# CH32F103xx register map
Vendor: WCH Ltd.; File version: 1.0
Registers are 32-bit, read-write, reset 0x0 unless marked. A register's access mark holds for its fields unless they carry their own. Offsets are from the block's base; [hi:lo] are bit positions; {n}, {i} and the like mark numbered series.

## DBG — Debug support
Base 0xE000D000
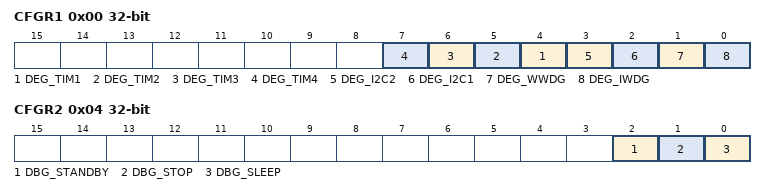
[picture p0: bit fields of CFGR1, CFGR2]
0x00 CFGR1 — DBGMCU_CFGR1
  [n+3] DEG_TIM{n} (n=1..4), [3] DEG_I2C2, [2] DEG_I2C1, [1] DEG_WWDG, [0] DEG_IWDG
0x04 CFGR2 — DBGMCU_CFGR2
  [2] DBG_STANDBY, [1] DBG_STOP, [0] DBG_SLEEP

## CRC — CRC calculation unit
Base 0x40023000
0x00 DATAR reset 0xFFFFFFFF — Data register
  [31:0] DR — Data Register
0x04 IDATAR — Independent Data register
  [7:0] IDR
0x08 CTLR wo — Control register
  [0] RESET — Reset bit

## FLASH
Base 0x40022000
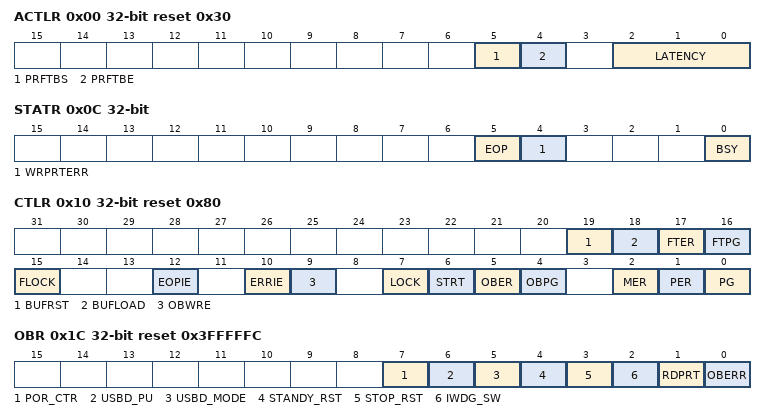
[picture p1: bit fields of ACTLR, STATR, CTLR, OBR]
0x00 ACTLR access per field reset 0x30 — Flash access control register
  [5] PRFTBS ro — Prefetch buffer status
  [4] PRFTBE rw — Prefetch buffer enable
  [2:0] LATENCY rw
0x04 KEYR wo — Flash key register
  [31:0] KEYR — FPEC key
0x08 OBKEYR wo — Flash option key register
  [31:0] OPTKEY — Option byte key
0x0C STATR access per field — Status register
  [5] EOP rw — End of operation
  [4] WRPRTERR rw — Write protection error
  [0] BSY ro — Busy
0x10 CTLR reset 0x80 — Control register
  [19] BUFRST — Buffer reset
  [18] BUFLOAD — Buffer load
  [17] FTER — Fast erase
  [16] FTPG — Fast programming
  [15] FLOCK — Fast programmable lock
  [12] EOPIE — End of operation interrupt enable
  [10] ERRIE — Error interrupt enable
  [9] OBWRE — Option bytes write enable
  [7] LOCK
  [6] STRT — Start
  [5] OBER — Option byte erase
  [4] OBPG — Option byte programming
  [2] MER — Mass Erase
  [1] PER — Page Erase
  [0] PG — Programming
0x14 ADDR wo — Flash address register
  [31:0] FAR — Flash Address
0x1C OBR ro reset 0x3FFFFFC — Option byte register
  [7] POR_CTR
  [6] USBD_PU
  [5] USBD_MODE
  [4] STANDY_RST
  [3] STOP_RST
  [2] IWDG_SW
  [1] RDPRT — Read protection
  [0] OBERR — Option byte error
0x20 WPR ro reset 0xFFFFFFFF — Write protection register
  [31:0] WRP — Write protect
0x24 MODEKEYR wo — Mode select register
  [31:0] MODEKEYR — Mode select

## PFIC — Programmable Fast Interrupt Controller
Base 0xE000E000
0x00 ISR1 ro — Interrupt Status Register
  [31:0] INTS — Interrupt ID Status
0x04 ISR2 ro — Interrupt Status Register
  [31:0] INTS — Interrupt ID Status
0x20 IPR1 ro — Interrupt Pending Register
  [31:0] PENDSTA
0x24 IPR2 ro — Interrupt Pending Register
  [31:0] PENDSTA
0x40 ITHRESDR — Interrupt Priority Register
  [7:0] THRESHOLD
0x44 FIBADDRR — Interrupt Fast Address Register
  [31:28] BASEADDR
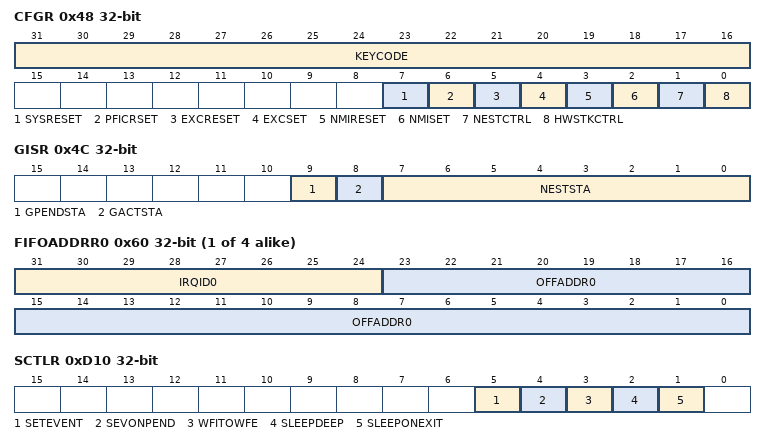
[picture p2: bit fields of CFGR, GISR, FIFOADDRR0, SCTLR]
0x48 CFGR access per field — Interrupt Config Register
  [31:16] KEYCODE wo, [7] SYSRESET wo, [6] PFICRSET wo, [5] EXCRESET wo, [4] EXCSET wo, [3] NMIRESET wo, [2] NMISET wo, [1] NESTCTRL rw, [0] HWSTKCTRL rw
0x4C GISR ro — Interrupt Global Register
  [9] GPENDSTA, [8] GACTSTA, [7:0] NESTSTA
{0x60+4i} FIFOADDRR{i} (i=0..3) — Interrupt {i} address Register
  [31:24] IRQID{i}, [23:0] OFFADDR{i}
0x100 IENR1 — Interrupt Setting Register
  [31:0] INTEN
0x104 IENR2 — Interrupt Setting Register
  [27:0] INTEN
0x180 IRER1 — Interrupt Clear Register
  [31:0] INTRSET
0x184 IRER2 — Interrupt Clear Register
  [27:0] INTRSET
0x200 IPSR1 — Interrupt Pending Register
  [31:0] PENDSET
0x204 IPSR2 — Interrupt Pending Register
  [27:0] PENDSET
0x280 IPRR1 — Interrupt Pending Clear Register
  [31:0] PENDRESET
0x284 IPRR2 — Interrupt Pending Clear Register
  [27:0] PENDRESET
0x300 IACTR1 — Interrupt ACTIVE Register
  [31:0] IACTS
0x304 IACTR2 — Interrupt ACTIVE Register
  [27:0] IACTS
0xD10 SCTLR — System Control Register
  [5] SETEVENT, [4] SEVONPEND, [3] WFITOWFE, [2] SLEEPDEEP, [1] SLEEPONEXIT
0x1000 STK_CTLR — System counter control register
  [0] STE — System counter enable
0x1004 STK_CNTL — System counter low register
0x1008 STK_CNTH — System counter high register
0x100C STK_CMPLR — System compare low register
  [31:0] CMPL
0x1010 STK_CMPHR — System compare high register
  [31:0] CMPH
